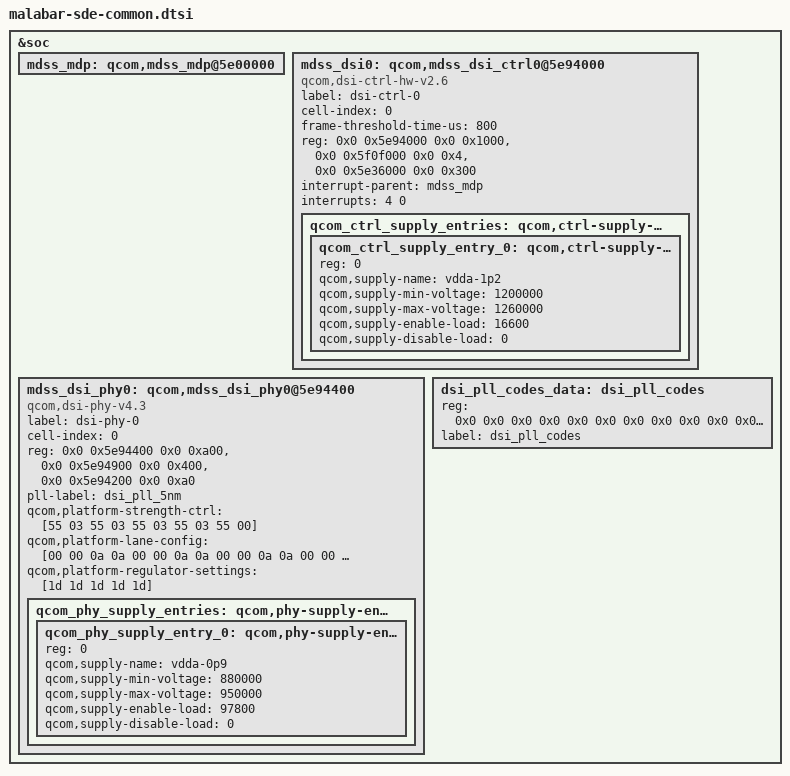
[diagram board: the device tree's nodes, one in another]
// SPDX-License-Identifier: BSD-3-Clause
/*
 * Copyright (c) Qualcomm Technologies, Inc. and/or its subsidiaries.
 */

#include <dt-bindings/interrupt-controller/arm-gic.h>

&soc {
	mdss_mdp: qcom,mdss_mdp@5e00000 {
	};

	mdss_dsi0: qcom,mdss_dsi_ctrl0@5e94000 {
		compatible = "qcom,dsi-ctrl-hw-v2.6";
		label = "dsi-ctrl-0";
		cell-index = <0>;
		frame-threshold-time-us = <800>;
		reg = <0x0 0x5e94000 0x0 0x1000>,
			  <0x0 0x5f0f000 0x0 0x4>,
			  <0x0 0x5e36000 0x0 0x300>;
		reg-names = "dsi_ctrl", "disp_cc_base", "mdp_intf_base";
		interrupt-parent = <&mdss_mdp>;
		interrupts = <4 0>;

		qcom_ctrl_supply_entries: qcom,ctrl-supply-entries {
			#address-cells = <1>;
			#size-cells = <0>;

			qcom_ctrl_supply_entry_0: qcom,ctrl-supply-entry@0 {
				reg = <0>;
				qcom,supply-name = "vdda-1p2";
				qcom,supply-min-voltage = <1200000>;
				qcom,supply-max-voltage = <1260000>;
				qcom,supply-enable-load = <16600>;
				qcom,supply-disable-load = <0>;
			};
		};
	};

	mdss_dsi_phy0: qcom,mdss_dsi_phy0@5e94400 {
		compatible = "qcom,dsi-phy-v4.3";
		label = "dsi-phy-0";
		cell-index = <0>;
		#clock-cells = <1>;
		reg = <0x0 0x5e94400 0x0 0xa00>,
		      <0x0 0x5e94900 0x0 0x400>,
		      <0x0 0x5e94200 0x0 0xa0>;
		reg-names = "dsi_phy", "pll_base", "dyn_refresh_base";
		pll-label = "dsi_pll_5nm";

		qcom,platform-strength-ctrl = [55 03
						55 03
						55 03
						55 03
						55 00];
		qcom,platform-lane-config = [00 00 0a 0a
						00 00 0a 0a
						00 00 0a 0a
						00 00 0a 0a
						00 00 8a 8a];
		qcom,platform-regulator-settings = [1d 1d 1d 1d 1d];

		qcom_phy_supply_entries: qcom,phy-supply-entries {
			#address-cells = <1>;
			#size-cells = <0>;
			qcom_phy_supply_entry_0: qcom,phy-supply-entry@0 {
				reg = <0>;
				qcom,supply-name = "vdda-0p9";
				qcom,supply-min-voltage = <880000>;
				qcom,supply-max-voltage = <950000>;
				qcom,supply-enable-load = <97800>;
				qcom,supply-disable-load = <0>;
			};
		};
	};

	dsi_pll_codes_data:dsi_pll_codes {
		#address-cells = <1>;
		#size-cells = <0>;
		reg = <0x0 0x0 0x0 0x0 0x0 0x0 0x0 0x0 0x0 0x0 0x0 0x0 0x0 0x0 0x0 0x0
			0x0 0x0 0x0 0x0 0x0 0x0 0x0 0x0 0x0 0x0 0x0 0x0 0x0 0x0 0x0 0x0
			0x0 0x0 0x0 0x0 0x0 0x0 0x0 0x0 0x0 0x0 0x0 0x0 0x0 0x0 0x0 0x0
			0x0 0x0 0x0 0x0 0x0 0x0 0x0 0x0 0x0 0x0 0x0 0x0 0x0 0x0 0x0 0x0
			0x0 0x0 0x0 0x0 0x0 0x0 0x0 0x0 0x0 0x0 0x0 0x0 0x0 0x0 0x0 0x0
			0x0 0x0 0x0 0x0 0x0 0x0 0x0 0x0 0x0 0x0 0x0 0x0 0x0 0x0 0x0 0x0
			0x0 0x0 0x0 0x0 0x0 0x0 0x0 0x0 0x0 0x0 0x0 0x0 0x0 0x0 0x0 0x0
			0x0 0x0 0x0 0x0 0x0 0x0 0x0 0x0 0x0 0x0 0x0 0x0 0x0 0x0 0x0 0x0>;
		label = "dsi_pll_codes";
	};
};

